# STC32G144K246 register map
Vendor: STC; File version: 2.0
Registers are 8-bit, read-write, no defined reset value unless marked. A register's access mark holds for its fields unless they carry their own. Offsets are from the block's base; [hi:lo] are bit positions.

## SPI2 — SPI2 接口
Base 0x007EF800
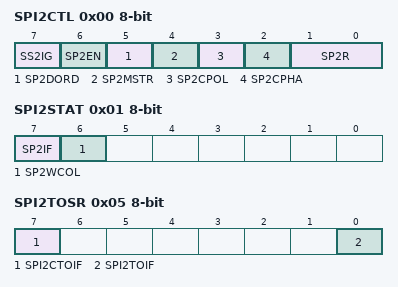
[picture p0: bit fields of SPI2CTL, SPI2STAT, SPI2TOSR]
0x00 SPI2CTL — SPI2控制寄存器
  [7] SS2IG — SS2 引脚功能控制位
    0=SS2 引脚确定器件是主机还是从机; 1=忽略SS2 引脚功能，使用SP2MSTR 确定器件是主机还是从机
  [6] SP2EN — SPI2 使能控制位
    0=关闭SPI2 功能; 1=使能SPI2 功能
  [5] SP2DORD — SPI2 数据位发送/接收的顺序
    0=先发送/接收数据的高位（MSB）; 1=先发送/接收数据的低位（LSB）
  [4] SP2MSTR — 器件主/从模式选择位 设置主机模式： 若SS2IG＝0，则SS2 管脚必须为高电平且设置SP2MSTR 为1 若SS2IG＝1，则只需要设置SP2MSTR 为1（忽略SS2 管脚的电平） 设置从机模式： 若SS2IG＝0，则SS2 管脚必须为低电平（与SP2MSTR 位无关） 若SS2IG＝1，则只
  [3] SP2CPOL — SPI2 时钟极性控制
    0=SCLK2 空闲时为低电平，SCLK2 的前时钟沿为上升沿，后时钟沿为下降沿; 1=SCLK2 空闲时为高电平，SCLK2 的前时钟沿为下降沿，后时钟沿为上升沿
  [2] SP2CPHA — SPI2 时钟相位控制
    0=数据 SS2 管脚为低电平驱动第一位数据并在 SCLK2 的后时钟沿改变数据，前时钟沿采样数据; 1=数据在SCLK2 的前时钟沿驱动，后时钟沿采样
  [1:0] SP2R — SPI2 时钟频率选择
    0=SPI2 输入时钟/4; 1=SPI2 输入时钟/8; 2=SPI2 输入时钟/16; 3=SPI2 输入时钟/2
0x01 SPI2STAT ro — SPI2状态寄存器
  [7] SP2IF — SPI2 数据传输完成中断请求标志。需要软件写“1”清零。
  [6] SP2WCOL — SPI2 写冲突标志位。 当SPI2 在进行数据传输的过程中写SP2DAT 寄存器时，硬件将此位置1。 注意：此标志位必须用户通过软件方式向此位写1 进行清零。
0x05 SPI2TOSR ro — SPI2从机超时状态寄存器
  [7] SPI2CTOIF — 写“1”清除SPI2 超时中断标志位SPI2TOIF。（只写）
  [0] SPI2TOIF — SPI2 超时中断请求标志位。标志位需要软件向SPI2CTOIF 位写“1”清零
0x08 SPI2_CLKDIV — SPI2时钟预分配寄存器
  [7:0] SPI2_CLKDIV — 高速SPI 时钟分频系数。(n=1,2,3)

## SPI3 — SPI3 接口
Base 0x007EF820
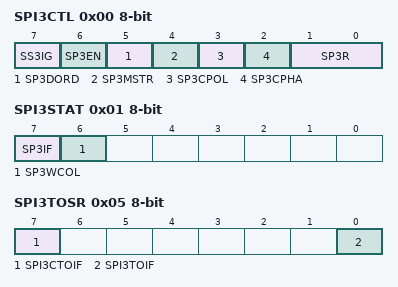
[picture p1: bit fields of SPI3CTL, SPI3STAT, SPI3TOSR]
0x00 SPI3CTL — SPI3控制寄存器
  [7] SS3IG — 尚未自动匹配到此字段的独立说明；请查看下方章节说明。
  [6] SP3EN — 尚未自动匹配到此字段的独立说明；请查看下方章节说明。
  [5] SP3DORD — 尚未自动匹配到此字段的独立说明；请查看下方章节说明。
  [4] SP3MSTR — 尚未自动匹配到此字段的独立说明；请查看下方章节说明。
  [3] SP3CPOL — 尚未自动匹配到此字段的独立说明；请查看下方章节说明。
  [2] SP3CPHA — 尚未自动匹配到此字段的独立说明；请查看下方章节说明。
  [1:0] SP3R — 尚未自动匹配到此字段的独立说明；请查看下方章节说明。
0x01 SPI3STAT ro — SPI3状态寄存器
  [7] SP3IF — SPI3 数据传输完成中断请求标志。需要软件写“1”清零。
  [6] SP3WCOL — SPI3 写冲突标志位。 当SPI3 在进行数据传输的过程中写SP3DAT 寄存器时，硬件将此位置1。 注意：此标志位必须用户通过软件方式向此位写1 进行清零。
0x05 SPI3TOSR ro — SPI3从机超时状态寄存器
  [7] SPI3CTOIF — 写“1”清除SPI3 超时中断标志位SP3TOIF。（只写）
  [0] SPI3TOIF — SPI3 超时中断请求标志位。标志位需要软件向SPI3CTOIF 位写“1”清零
0x08 SPI3_CLKDIV — SPI3时钟预分配寄存器
  [7:0] SPI3_CLKDIV — 高速SPI 时钟分频系数。(n=1,2,3)

## QSPI — QSPI 配置和 FIFO 水位；SR1 在自动轮询时有读副作用
Base 0x007EF900
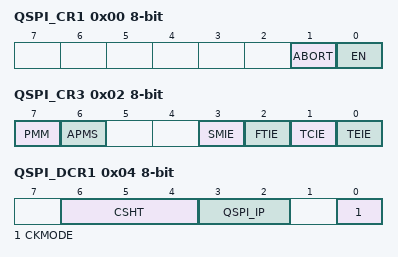
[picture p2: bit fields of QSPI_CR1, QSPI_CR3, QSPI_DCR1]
0x00 QSPI_CR1 ro — QSPI控制寄存器1
  [1] ABORT — 中止请求。该位中止执行中的命令序列。在中止完成时自动复位。该位可停止当前的传输。在 轮询模式或内存映射模式下，该位也用以复位APM 位或DM 位。
    0=不请求中止; 1=请求中止
  [0] EN — QSPI 功能使能控制位
    0=禁止QSPI; 1=使能QSPI
0x01 QSPI_CR2 ro — QSPI控制寄存器2
  [4:0] FTHRES — FIFO 阈值级别（FIFO threshold level）。 定义在间接模式下FIFO 中将导致FIFO 阈值标志FTF 置1 的字节数阈值。 在间接写入模式下（FMODE = 00）
0x02 QSPI_CR3 ro — QSPI控制寄存器3
  [7] PMM — 轮询匹配模式（Polling match mode）。 该位指示在自动轮询模式期间用来确定是否匹配的方法。仅可在BUSY = 0 时修改该位。
    0=AND 匹配模式。; 1=OR 匹配模式。
  [6] APMS — 自动轮询模式停止（Automatic poll mode stop） 该位确定在匹配后自动轮询是否停止。仅可在BUSY = 0 时修改该位。
    0=仅通过中止或禁用QSPI 停止自动轮询模式。; 1=发生匹配时，自动轮询模式停止。
  [3] SMIE — QSPI状态匹配中断允许位。
    0=禁止QSPI 状态匹配中断; 1=允许QSPI 状态匹配中断
  [2] FTIE — QSPI FIFO阈值中断允许位。
    0=禁止QSPI FIFO 阈值中断; 1=允许QSPI FIFO 阈值中断
  [1] TCIE — QSPI传输完成中断允许位。
    0=禁止QSPI 传输完成中断; 1=允许QSPI 传输完成中断
  [0] TEIE — QSPI传输错误中断允许位。
    0=禁止QSPI 传输错误中断; 1=允许QSPI 传输错误中断
0x03 QSPI_CR4 ro — QSPI控制寄存器4
  [7:0] PSCR — 时钟预分频器（Clock prescaler）。 对于奇数时钟分频系数，CLK 的占空比并非50%。时钟信号的高电平持续时间比低电平持续时间多 一个周期。仅可在BUSY = 0 时修改该位。
0x04 QSPI_DCR1 ro — QSPI器件配置寄存器1
  [6:4] CSHT — 片选高电平时间（Chip select high time）。仅可在BUSY = 0 时修改该位。
  [3:2] QSPI_IP — QSPI中断优先级控制位
    0=QSPI 中断优先级为0 级（最低级）; 1=QSPI 中断优先级为1 级（较低级）; 2=QSPI 中断优先级为2 级（较高级）; 3=QSPI 中断优先级为3 级（最高级）
  [0] CKMODE — SPI 模式0/模式3（Mode 0 / mode 3）选择位。该位指示CLK 在nCS=1 时的电平。仅可在 BUSY = 0 时修改该位。
    0=nCS 为高电平（片选释放）时，CLK 必须保持低电平。这称为模式0。; 1=nCS 为高电平（片选释放）时，CLK 必须保持高电平。这称为模式3。
0x05 QSPI_DCR2 ro — QSPI器件配置寄存器2
  [4:0] FSIZE — 配置外部Flash 存储器的大小。仅可在BUSY = 0 时修改该位。 [FSIZE+1] Flash 中的字节数 = 2 FSIZE+1 是对 Flash 寻址所需的地址位数。在间接模式下，Flash 容量最高可达4GB（使用32 位进 行寻址）。
0x07 QSPI_SR2 ro — QSPI状态寄存器2
  [5:0] FLEVEL — FIFO 级别（FIFO level） 该字段给出FIFO 中的有效字节数。FIFO 为空时FLEVEL = 0；写满时FLEVEL = 32 在自动状态轮询模式下，FLEVEL 为零。
